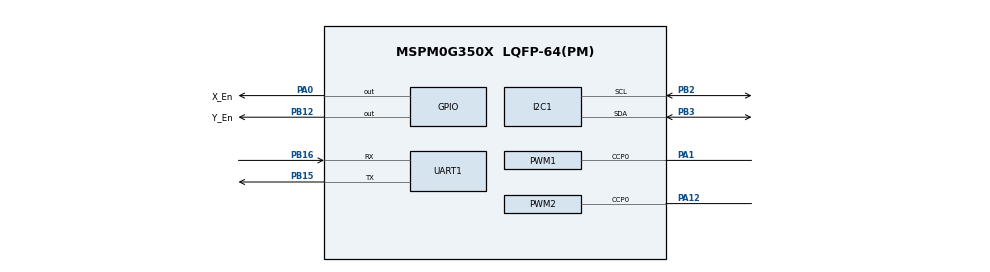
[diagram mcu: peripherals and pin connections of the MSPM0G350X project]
/**
 * @cliArgs --device "MSPM0G350X" --part "Default" --package "LQFP-64(PM)" --product "mspm0_sdk@2.05.01.01"
 * @versions {"tool":"1.23.1+4034"}
 */

/**
 * Import the modules used in this configuration.
 */
const GPIO    = scripting.addModule("/ti/driverlib/GPIO", {}, false);
const GPIO1   = GPIO.addInstance();
const I2C     = scripting.addModule("/ti/driverlib/I2C", {}, false);
const I2C1    = I2C.addInstance();
const PWM     = scripting.addModule("/ti/driverlib/PWM", {}, false);
const PWM1    = PWM.addInstance();
const PWM2    = PWM.addInstance();
const SYSCTL  = scripting.addModule("/ti/driverlib/SYSCTL");
const SYSTICK = scripting.addModule("/ti/driverlib/SYSTICK");
const UART    = scripting.addModule("/ti/driverlib/UART", {}, false);
const UART1   = UART.addInstance();

/**
 * Write custom configuration values to the imported modules.
 */
const divider6       = system.clockTree["PLL_CLK2X_DIV"];
divider6.divideValue = 4;

const divider7       = system.clockTree["PLL_PDIV"];
divider7.divideValue = 2;

const divider9       = system.clockTree["UDIV"];
divider9.divideValue = 2;

const multiplier2         = system.clockTree["PLL_QDIV"];
multiplier2.multiplyValue = 10;

const mux8       = system.clockTree["HSCLKMUX"];
mux8.inputSelect = "HSCLKMUX_SYSPLL2X";

GPIO1.$name                          = "Motor";
GPIO1.associatedPins.create(4);
GPIO1.associatedPins[0].$name        = "X_Dir";
GPIO1.associatedPins[0].assignedPin  = "2";
GPIO1.associatedPins[0].assignedPort = "PORTA";
GPIO1.associatedPins[1].$name        = "Y_Dir";
GPIO1.associatedPins[1].assignedPort = "PORTB";
GPIO1.associatedPins[1].assignedPin  = "13";
GPIO1.associatedPins[2].$name        = "X_En";
GPIO1.associatedPins[2].initialValue = "SET";
GPIO1.associatedPins[2].pin.$assign  = "PA0";
GPIO1.associatedPins[3].$name        = "Y_En";
GPIO1.associatedPins[3].initialValue = "SET";
GPIO1.associatedPins[3].pin.$assign  = "PB12";

const Board = scripting.addModule("/ti/driverlib/Board", {}, false);

I2C1.$name                             = "I2C_OLED";
I2C1.basicEnableController             = true;
I2C1.basicControllerStandardBusSpeed   = "Fast";
I2C1.peripheral.sdaPin.$assign         = "PB3";
I2C1.peripheral.sclPin.$assign         = "PB2";
I2C1.sdaPinConfig.$name                = "ti_driverlib_gpio_GPIOPinGeneric4";
I2C1.sdaPinConfig.hideOutputInversion  = scripting.forceWrite(false);
I2C1.sdaPinConfig.onlyInternalResistor = scripting.forceWrite(false);
I2C1.sdaPinConfig.passedPeripheralType = scripting.forceWrite("Digital");
I2C1.sclPinConfig.$name                = "ti_driverlib_gpio_GPIOPinGeneric5";
I2C1.sclPinConfig.hideOutputInversion  = scripting.forceWrite(false);
I2C1.sclPinConfig.onlyInternalResistor = scripting.forceWrite(false);
I2C1.sclPinConfig.passedPeripheralType = scripting.forceWrite("Digital");

PWM1.ccIndex                            = [0];
PWM1.$name                              = "PWM_X";
PWM1.timerStartTimer                    = true;
PWM1.timerCount                         = 40000;
PWM1.PWM_CHANNEL_0.$name                = "ti_driverlib_pwm_PWMTimerCC0";
PWM1.PWM_CHANNEL_0.dutyCycle            = 50;
PWM1.ccp0PinConfig.$name                = "ti_driverlib_gpio_GPIOPinGeneric0";
PWM1.ccp0PinConfig.direction            = scripting.forceWrite("OUTPUT");
PWM1.ccp0PinConfig.hideOutputInversion  = scripting.forceWrite(false);
PWM1.ccp0PinConfig.onlyInternalResistor = scripting.forceWrite(false);
PWM1.ccp0PinConfig.passedPeripheralType = scripting.forceWrite("Digital");
PWM1.peripheral.ccp0Pin.$assign         = "PA1";

PWM2.ccIndex                            = [0];
PWM2.$name                              = "PWM_Y";
PWM2.timerStartTimer                    = true;
PWM2.timerCount                         = 40000;
PWM2.PWM_CHANNEL_0.$name                = "ti_driverlib_pwm_PWMTimerCC1";
PWM2.PWM_CHANNEL_0.dutyCycle            = 50;
PWM2.ccp0PinConfig.direction            = scripting.forceWrite("OUTPUT");
PWM2.ccp0PinConfig.hideOutputInversion  = scripting.forceWrite(false);
PWM2.ccp0PinConfig.onlyInternalResistor = scripting.forceWrite(false);
PWM2.ccp0PinConfig.passedPeripheralType = scripting.forceWrite("Digital");
PWM2.ccp0PinConfig.$name                = "ti_driverlib_gpio_GPIOPinGeneric1";
PWM2.peripheral.ccp0Pin.$assign         = "PA12";

SYSCTL.forceDefaultClkConfig = true;
SYSCTL.clockTreeEn           = true;

SYSTICK.periodEnable    = true;
SYSTICK.period          = 80000;
SYSTICK.interruptEnable = true;
SYSTICK.systickEnable   = true;

UART1.targetBaudRate                   = 115200;
UART1.$name                            = "UART2";
UART1.enabledInterrupts                = ["RX"];
UART1.peripheral.$assign               = "UART2";
UART1.peripheral.rxPin.$assign         = "PB16";
UART1.peripheral.txPin.$assign         = "PB15";
UART1.txPinConfig.direction            = scripting.forceWrite("OUTPUT");
UART1.txPinConfig.hideOutputInversion  = scripting.forceWrite(false);
UART1.txPinConfig.onlyInternalResistor = scripting.forceWrite(false);
UART1.txPinConfig.passedPeripheralType = scripting.forceWrite("Digital");
UART1.txPinConfig.$name                = "ti_driverlib_gpio_GPIOPinGeneric2";
UART1.rxPinConfig.hideOutputInversion  = scripting.forceWrite(false);
UART1.rxPinConfig.onlyInternalResistor = scripting.forceWrite(false);
UART1.rxPinConfig.passedPeripheralType = scripting.forceWrite("Digital");
UART1.rxPinConfig.$name                = "ti_driverlib_gpio_GPIOPinGeneric3";

/**
 * Pinmux solution for unlocked pins/peripherals. This ensures that minor changes to the automatic solver in a future
 * version of the tool will not impact the pinmux you originally saw.  These lines can be completely deleted in order to
 * re-solve from scratch.
 */
GPIO1.associatedPins[0].pin.$suggestSolution = "PA2";
GPIO1.associatedPins[1].pin.$suggestSolution = "PB13";
Board.peripheral.$suggestSolution            = "DEBUGSS";
Board.peripheral.swclkPin.$suggestSolution   = "PA20";
Board.peripheral.swdioPin.$suggestSolution   = "PA19";
I2C1.peripheral.$suggestSolution             = "I2C1";
PWM1.peripheral.$suggestSolution             = "TIMG8";
PWM2.peripheral.$suggestSolution             = "TIMG0";
